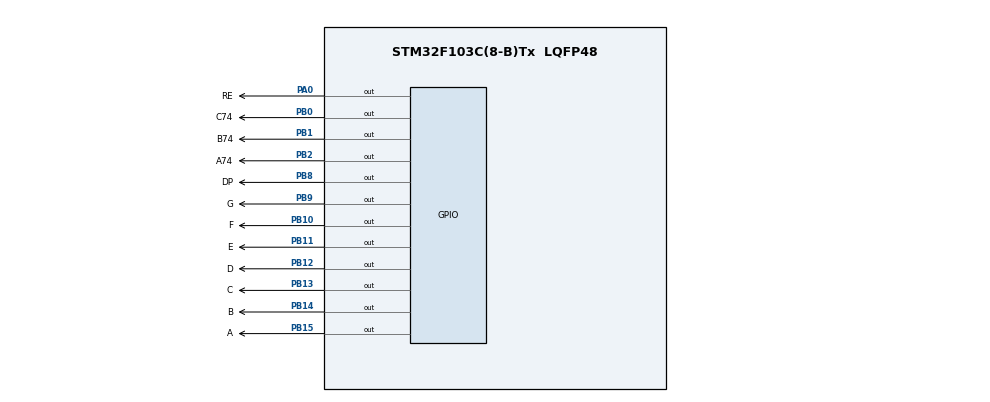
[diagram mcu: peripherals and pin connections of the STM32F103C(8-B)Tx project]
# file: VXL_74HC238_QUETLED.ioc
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Mcu.Family=STM32F1
Mcu.Name=STM32F103C(8-B)Tx
Mcu.Package=LQFP48
NVIC.PriorityGroup=NVIC_PRIORITYGROUP_4
PA0-WKUP.GPIO_Label=RE
PA0-WKUP.Signal=GPIO_Output
PA13.Mode=Serial_Wire
PA13.Signal=SYS_JTMS-SWDIO
PA14.Mode=Serial_Wire
PA14.Signal=SYS_JTCK-SWCLK
PB0.GPIO_Label=C74
PB0.Signal=GPIO_Output
PB1.GPIO_Label=B74
PB1.Signal=GPIO_Output
PB10.GPIO_Label=F
PB10.Signal=GPIO_Output
PB11.GPIO_Label=E
PB11.Signal=GPIO_Output
PB12.GPIO_Label=D
PB12.Signal=GPIO_Output
PB13.GPIO_Label=C
PB13.Signal=GPIO_Output
PB14.GPIO_Label=B
PB14.Signal=GPIO_Output
PB15.GPIO_Label=A
PB15.Signal=GPIO_Output
PB2.GPIO_Label=A74
PB2.Signal=GPIO_Output
PB8.GPIO_Label=DP
PB8.Signal=GPIO_Output
PB9.GPIO_Label=G
PB9.Signal=GPIO_Output
ProjectManager.HeapSize=0x200
ProjectManager.StackSize=0x400
ProjectManager.TargetToolchain=MDK-ARM V5.32
RCC.APB1Freq_Value=8000000
RCC.APB2Freq_Value=8000000
board=custom

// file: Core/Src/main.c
/* USER CODE BEGIN Header */
/**
  ******************************************************************************
  * @file           : main.c
  * @brief          : Main program body
  ******************************************************************************
  * @attention
  *
  * Copyright (c) 2023 STMicroelectronics.
  * All rights reserved.
  *
  * This software is licensed under terms that can be found in the LICENSE file
  * in the root directory of this software component.
  * If no LICENSE file comes with this software, it is provided AS-IS.
  *
  ******************************************************************************
  */
/* USER CODE END Header */
#include "main.h"

/* USER CODE BEGIN PV */

// Define pin arrays
GPIO_TypeDef* gpio_ports[] = {A_GPIO_Port, B_GPIO_Port, C_GPIO_Port, D_GPIO_Port, E_GPIO_Port, F_GPIO_Port, G_GPIO_Port};
uint16_t gpio_pins[] = {A_Pin, B_Pin, C_Pin, D_Pin, E_Pin, F_Pin, G_Pin};
GPIO_TypeDef* gpio_ports74[] = {A74_GPIO_Port, B74_GPIO_Port, C74_GPIO_Port};
uint16_t gpio_pins74[] = {A74_Pin, B74_Pin, C74_Pin};

/* USER CODE END PV */

void SystemClock_Config(void);
static void MX_GPIO_Init(void);

/* USER CODE BEGIN 0 */
// Function to display a digit
void displayDigit(uint8_t digit, uint8_t a, uint8_t b, uint8_t c, uint8_t d, uint8_t e, uint8_t f, uint8_t g) {
  // Set pin values
  uint8_t pin_values[] = {a, b, c, d, e, f, g};
  for (uint8_t i = 0; i < 7; i++) {
    HAL_GPIO_WritePin(gpio_ports[i], gpio_pins[i], pin_values[i]);
  }

  // Set 74HC595 pins
  HAL_GPIO_WritePin(gpio_ports74[0], gpio_pins74[0], digit&1);
  HAL_GPIO_WritePin(gpio_ports74[1], gpio_pins74[1], digit>>1&1);
  HAL_GPIO_WritePin(gpio_ports74[2], gpio_pins74[2], digit>>2&1);

  // Enable display
  //HAL_GPIO_WritePin(RE_GPIO_Port, RE_Pin, 1);
  HAL_Delay(1);
  //HAL_GPIO_WritePin(RE_GPIO_Port, RE_Pin, 0);

	GPIOB->ODR=0x0000;
}
/* USER CODE END 0 */

int main(void)
{

  /* MCU Configuration--------------------------------------------------------*/

  /* Reset of all peripherals, Initializes the Flash interface and the Systick. */
  HAL_Init();

  /* Configure the system clock */
  SystemClock_Config();

  /* Initialize all configured peripherals */
  MX_GPIO_Init();
  /* USER CODE BEGIN 2 */
	//HAL_GPIO_WritePin(RE_GPIO_Port,RE_Pin,1);
  /* USER CODE END 2 */

  /* Infinite loop */
  while (1)
  {
		displayDigit(0, 1, 1, 0, 1, 1, 0, 1);

		displayDigit(1, 1, 1, 1, 1, 1, 1, 0);

		displayDigit(2, 0, 1, 1, 0, 0, 0, 0);

		displayDigit(3, 0, 1, 1, 0, 0, 1, 1);

		displayDigit(4, 1, 0, 1, 1, 1, 1, 1);

		displayDigit(5, 0, 1, 1, 0, 0, 1, 1);

		displayDigit(6, 1, 1, 1, 0, 0, 0, 0);

		displayDigit(7, 1, 1, 1, 1, 0, 1, 1);
  }
}

void SystemClock_Config(void)
{
  RCC_OscInitTypeDef RCC_OscInitStruct = {0};
  RCC_ClkInitTypeDef RCC_ClkInitStruct = {0};

  /** Initializes the RCC Oscillators according to the specified parameters
  * in the RCC_OscInitTypeDef structure.
  */
  RCC_OscInitStruct.OscillatorType = RCC_OSCILLATORTYPE_HSI;
  RCC_OscInitStruct.HSIState = RCC_HSI_ON;
  RCC_OscInitStruct.HSICalibrationValue = RCC_HSICALIBRATION_DEFAULT;
  RCC_OscInitStruct.PLL.PLLState = RCC_PLL_NONE;
  if (HAL_RCC_OscConfig(&RCC_OscInitStruct) != HAL_OK)
  {
    Error_Handler();
  }

  /** Initializes the CPU, AHB and APB buses clocks
  */
  RCC_ClkInitStruct.ClockType = RCC_CLOCKTYPE_HCLK|RCC_CLOCKTYPE_SYSCLK
                              |RCC_CLOCKTYPE_PCLK1|RCC_CLOCKTYPE_PCLK2;
  RCC_ClkInitStruct.SYSCLKSource = RCC_SYSCLKSOURCE_HSI;
  RCC_ClkInitStruct.AHBCLKDivider = RCC_SYSCLK_DIV1;
  RCC_ClkInitStruct.APB1CLKDivider = RCC_HCLK_DIV1;
  RCC_ClkInitStruct.APB2CLKDivider = RCC_HCLK_DIV1;

  if (HAL_RCC_ClockConfig(&RCC_ClkInitStruct, FLASH_LATENCY_0) != HAL_OK)
  {
    Error_Handler();
  }
}

static void MX_GPIO_Init(void)
{
  GPIO_InitTypeDef GPIO_InitStruct = {0};

  /* GPIO Ports Clock Enable */
  __HAL_RCC_GPIOC_CLK_ENABLE();
  __HAL_RCC_GPIOD_CLK_ENABLE();
  __HAL_RCC_GPIOA_CLK_ENABLE();
  __HAL_RCC_GPIOB_CLK_ENABLE();

  /*Configure GPIO pin Output Level */
  HAL_GPIO_WritePin(RE_GPIO_Port, RE_Pin, GPIO_PIN_RESET);

  /*Configure GPIO pin Output Level */
  HAL_GPIO_WritePin(GPIOB, C74_Pin|B74_Pin|A74_Pin|F_Pin
                          |E_Pin|D_Pin|C_Pin|B_Pin
                          |A_Pin|DP_Pin|G_Pin, GPIO_PIN_RESET);

  /*Configure GPIO pins : PC13 PC14 PC15 */
  GPIO_InitStruct.Pin = GPIO_PIN_13|GPIO_PIN_14|GPIO_PIN_15;
  GPIO_InitStruct.Mode = GPIO_MODE_ANALOG;
  HAL_GPIO_Init(GPIOC, &GPIO_InitStruct);

  /*Configure GPIO pins : PD0 PD1 */
  GPIO_InitStruct.Pin = GPIO_PIN_0|GPIO_PIN_1;
  GPIO_InitStruct.Mode = GPIO_MODE_ANALOG;
  HAL_GPIO_Init(GPIOD, &GPIO_InitStruct);

  /*Configure GPIO pin : RE_Pin */
  GPIO_InitStruct.Pin = RE_Pin;
  GPIO_InitStruct.Mode = GPIO_MODE_OUTPUT_PP;
  GPIO_InitStruct.Pull = GPIO_NOPULL;
  GPIO_InitStruct.Speed = GPIO_SPEED_FREQ_LOW;
  HAL_GPIO_Init(RE_GPIO_Port, &GPIO_InitStruct);

  /*Configure GPIO pins : PA1 PA2 PA3 PA4
                           PA5 PA6 PA7 PA8
                           PA9 PA10 PA11 PA12
                           PA15 */
  GPIO_InitStruct.Pin = GPIO_PIN_1|GPIO_PIN_2|GPIO_PIN_3|GPIO_PIN_4
                          |GPIO_PIN_5|GPIO_PIN_6|GPIO_PIN_7|GPIO_PIN_8
                          |GPIO_PIN_9|GPIO_PIN_10|GPIO_PIN_11|GPIO_PIN_12
                          |GPIO_PIN_15;
  GPIO_InitStruct.Mode = GPIO_MODE_ANALOG;
  HAL_GPIO_Init(GPIOA, &GPIO_InitStruct);

  /*Configure GPIO pins : C74_Pin B74_Pin A74_Pin F_Pin
                           E_Pin D_Pin C_Pin B_Pin
                           A_Pin DP_Pin G_Pin */
  GPIO_InitStruct.Pin = C74_Pin|B74_Pin|A74_Pin|F_Pin
                          |E_Pin|D_Pin|C_Pin|B_Pin
                          |A_Pin|DP_Pin|G_Pin;
  GPIO_InitStruct.Mode = GPIO_MODE_OUTPUT_PP;
  GPIO_InitStruct.Pull = GPIO_NOPULL;
  GPIO_InitStruct.Speed = GPIO_SPEED_FREQ_LOW;
  HAL_GPIO_Init(GPIOB, &GPIO_InitStruct);

  /*Configure GPIO pins : PB3 PB4 PB5 PB6
                           PB7 */
  GPIO_InitStruct.Pin = GPIO_PIN_3|GPIO_PIN_4|GPIO_PIN_5|GPIO_PIN_6
                          |GPIO_PIN_7;
  GPIO_InitStruct.Mode = GPIO_MODE_ANALOG;
  HAL_GPIO_Init(GPIOB, &GPIO_InitStruct);

  /*Configure peripheral I/O remapping */
  __HAL_AFIO_REMAP_PD01_ENABLE();

}

void Error_Handler(void)
{
  __disable_irq();
  while (1)
  {
  }
}
